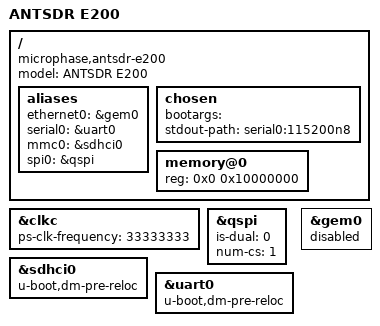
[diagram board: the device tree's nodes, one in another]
// SPDX-License-Identifier: GPL-2.0+
/*
 * U-Boot device tree for ANTSDR E200.
 *
 * The board console is PS UART0 on MIO 14/15.
 */
/dts-v1/;
#include "zynq-7000.dtsi"

/ {
	model = "ANTSDR E200";
	compatible = "microphase,antsdr-e200", "xlnx,zynq-7000";

	aliases {
		ethernet0 = &gem0;
		serial0 = &uart0;
		mmc0 = &sdhci0;
		spi0 = &qspi;
	};

	chosen {
		bootargs = "";
		stdout-path = "serial0:115200n8";
	};

	memory@0 {
		device_type = "memory";
		reg = <0x0 0x10000000>;
	};
};

&clkc {
	ps-clk-frequency = <33333333>;
};

&qspi {
	status = "okay";
	is-dual = <0>;
	num-cs = <1>;
};

&sdhci0 {
	u-boot,dm-pre-reloc;
	status = "okay";
};

&uart0 {
	u-boot,dm-pre-reloc;
	status = "okay";
};

// The EMIO bridge is loaded by uEnv after U-Boot starts. Keep GEM disabled
// in U-Boot's control DT so pre-bitstream probing cannot access absent PL.
// Linux enables GEM0 with the converter and Realtek PHY drivers.
&gem0 {
    status = "disabled";
};
